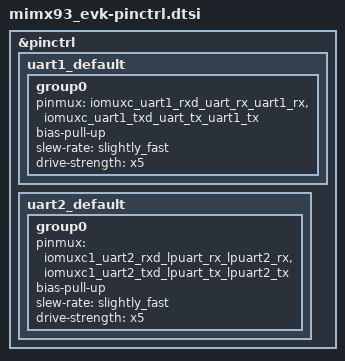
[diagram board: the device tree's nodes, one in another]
/*
 * Copyright 2022,2024 NXP

 * SPDX-License-Identifier: Apache-2.0
 */

#include <nxp/nxp_imx/mimx9352cvuxk-pinctrl.dtsi>

&pinctrl {
	uart1_default: uart1_default {
		group0 {
			pinmux = <&iomuxc_uart1_rxd_uart_rx_uart1_rx>,
				<&iomuxc_uart1_txd_uart_tx_uart1_tx>;
			bias-pull-up;
			slew-rate = "slightly_fast";
			drive-strength = "x5";
		};
	};

	uart2_default: uart2_default {
		group0 {
			pinmux = <&iomuxc1_uart2_rxd_lpuart_rx_lpuart2_rx>,
				<&iomuxc1_uart2_txd_lpuart_tx_lpuart2_tx>;
			bias-pull-up;
			slew-rate = "slightly_fast";
			drive-strength = "x5";
		};
	};
};
